# STM32U575xx register map
File version: 1.0
Registers are 32-bit, read-write, reset 0x0 unless marked. A register's access mark holds for its fields unless they carry their own. Offsets are from the block's base; [hi:lo] are bit positions; {n}, {i} and the like mark numbered series; 'fields as' and 'values as' point back to an identical list.

## FMC_Bank1E_R — Flexible Memory Controller Bank1E
Base 0x420D0504
Same registers: FMC_Bank1E_R_S 0x520D0504
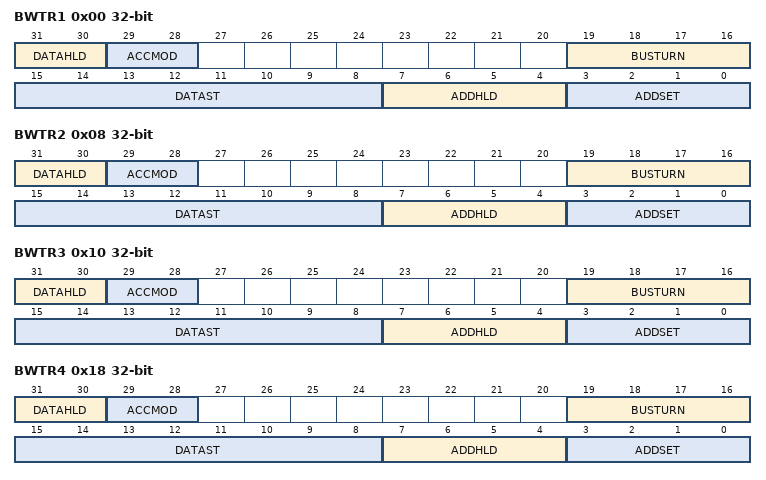
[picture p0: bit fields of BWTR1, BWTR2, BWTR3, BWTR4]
0x00 BWTR1 — NOR/PSRAM write timing registers
  [31:30] DATAHLD — DATAHLD[1:0] bits (Data hold phase duration)
  [29:28] ACCMOD — ACCMOD[1:0] bits (Access mode)
  [19:16] BUSTURN — BUSTURN[3:0] bits (Bus turnaround phase duration)
  [15:8] DATAST — DATAST [3:0] bits (Data-phase duration)
  [7:4] ADDHLD — ADDHLD[3:0] bits (Address-hold phase duration)
  [3:0] ADDSET — ADDSET[3:0] bits (Address setup phase duration)
0x08 BWTR2 — NOR/PSRAM write timing registers
  fields as BWTR1
0x10 BWTR3 — NOR/PSRAM write timing registers
  fields as BWTR1
0x18 BWTR4 — NOR/PSRAM write timing registers
  fields as BWTR1

## SYSCFG — System configuration controller
Base 0x46000400
Same registers: SYSCFG_S 0x56000400
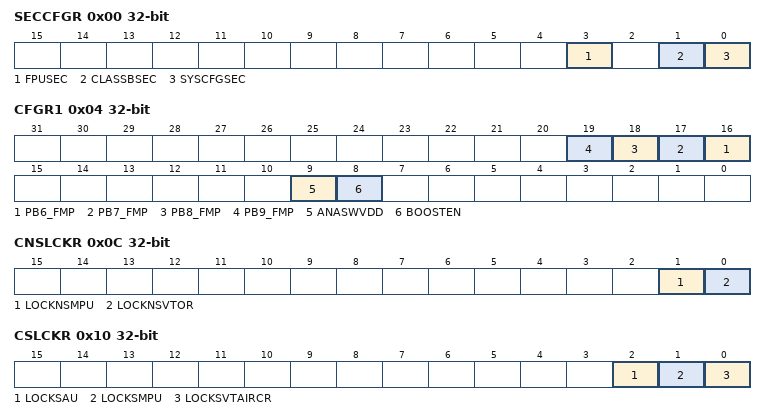
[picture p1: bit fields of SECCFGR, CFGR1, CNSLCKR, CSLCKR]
0x00 SECCFGR — SYSCFG secure configuration register
  [3] FPUSEC — FPU SYSCFG security enable
  [1] CLASSBSEC — ClassB SYSCFG security enable
  [0] SYSCFGSEC — SYSCFG clock control security enable
0x04 CFGR1 — SYSCFG configuration register 1
  [n+10] PB{n}_FMP (n=6..9) — PB{n} Fast mode plus
  [9] ANASWVDD — GPIO analog switch control voltage selection
  [8] BOOSTEN — I/O analog switch voltage booster enable
0x08 FPUIMR — SYSCFG FPU interrupt mask register
  [5:0] FPU_IE — All FPU interrupts enable
0x0C CNSLCKR — SYSCFG CPU non-secure lock register
  [1] LOCKNSMPU — Disable Non-Secure MPU registers writes by SW or debug agent
  [0] LOCKNSVTOR — Disable VTOR_NS register writes by SW or debug agent
0x10 CSLCKR — SYSCFG CPU secure lock register
  [2] LOCKSAU — Disable changes to SAU registers
  [1] LOCKSMPU — Disable changes to the secure MPU registers writes by SW or debug agent
  [0] LOCKSVTAIRCR — Disable changes to the secure vector table address, handling of system faults
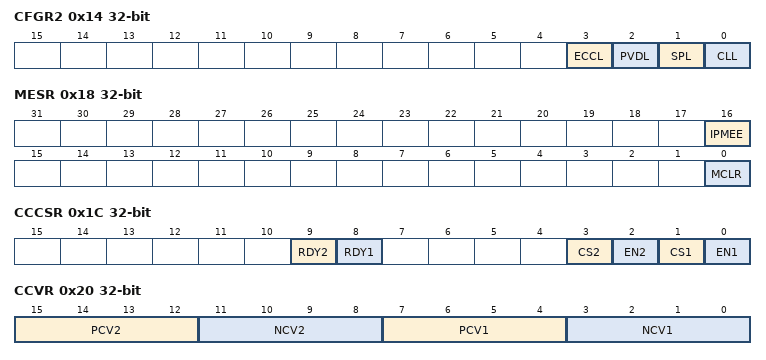
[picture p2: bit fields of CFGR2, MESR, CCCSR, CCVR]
0x14 CFGR2 — SYSCFG configuration register 2
  [3] ECCL — ECC Lock
  [2] PVDL — PVD Lock
  [1] SPL — SRAM ECC Lock
  [0] CLL — Core Lockup Lock
0x18 MESR — SYSCFG Memory Erase Status register
  [16] IPMEE — Status of End of Erase for ICache and PKA RAMs
  [0] MCLR — Status of Erase after Reset
0x1C CCCSR — SYSCFG Conpensaion Cell Control&Status register
  [9] RDY2 — VDDIO compensation cell ready flag
  [8] RDY1 — VDD compensation cell ready flag
  [3] CS2 — Code selection for VDDIO power rail
  [2] EN2 — Enable compensation cell for VDDIO power rail
  [1] CS1 — Code selection for VDD power rail
  [0] EN1 — Enable compensation cell for VDD power rail
0x20 CCVR — SYSCFG Conpensaion Cell value register
  [15:12] PCV2 — PMOS compensation value for VDDIO Power Rail
  [11:8] NCV2 — NMOS compensation value for VDDIO Power Rail
  [7:4] PCV1 — PMOS compensation value for VDD Power Rail
  [3:0] NCV1 — NMOS compensation value for VDD Power Rail
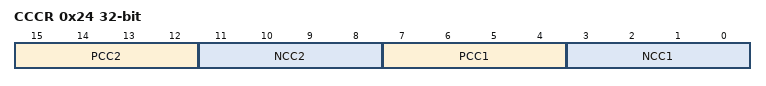
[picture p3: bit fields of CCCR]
0x24 CCCR — SYSCFG Conpensaion Cell Code register
  [15:12] PCC2 — PMOS compensation code for VDDIO Power Rail
  [11:8] NCC2 — NMOS compensation code for VDDIO Power Rail
  [7:4] PCC1 — PMOS compensation code for VDD Power Rail
  [3:0] NCC1 — NMOS compensation code for VDD Power Rail
0x2C RSSCMDR — SYSCFG RSS command mode register
  [15:0] RSSCMD — RSS command

## OPAMP12_COMMON
Base 0x46005000
Same registers: OPAMP12_COMMON_S 0x56005000
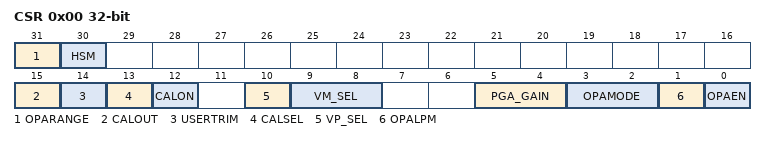
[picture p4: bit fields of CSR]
0x00 CSR — OPAMP control/status register, used for bits common to several OPAMP instances
  [31] OPARANGE — Operational amplifier range setting
    0=LOW (Power supply range low); 1=HIGH (Power supply range high - recommended for performance purpose)
  [30] HSM — Operational amplifier high speed mode
  [15] CALOUT — Operational amplifier calibration output
  [14] USERTRIM — User trimming enable
    0=FACTORY (OPAMP trimming factors set to factory values); 1=USER (OPAMP trimming factors set to user values)
  [13] CALSEL — Calibration selection
  [12] CALON — Calibration mode enable
    0=FUNCTIONAL (OPAMP functional mode); 1=CALIBRATION (OPAMP calibration mode)
  [10] VP_SEL — Non inverted input selection
    0=IO0 (OPAMP non inverting input connected to GPIO pin (pin PA0 for OPAMP1, pin PA6 for OPAMP2)); 1=DAC (OPAMP non inverting input connected to DAC1 channel output(channel1 for OPAMP1, channel2 for OPAMP2))
  [9:8] VM_SEL — Inverting input selection
    0=IO0 (OPAMP inverting input connected to GPIO pin (valid also in PGA mode for filtering). Note: OPAMP inverting input is used with OPAMP in mode standalone or PGA with external capacitors for filtering circuit. Otherwise (OPAMP in mode follower), OPAMP inverting input is not used (not connected to GPIO pin).); 1=IO1 (OPAMP inverting input (low leakage input) connected to GPIO pin (available only on package BGA132). Note: OPAMP inverting input is used with OPAMP in mode standalone or PGA with external capacitors for filtering circuit. Otherwise (OPAMP in mode follower), OPAMP inverting input is not used (not connected to GPIO pin).); 2=CONNECT_NO (OPAMP inverting input not externally connected (intended for OPAMP in mode follower or PGA without external capacitors for filtering))
  [5:4] PGA_GAIN — Operational amplifier Programmable amplifier gain value
    0=GAIN_2 (OPAMP PGA gain 2); 1=GAIN_4 (OPAMP PGA gain 4); 2=GAIN_8 (OPAMP PGA gain 8); 3=GAIN_16 (OPAMP PGA gain 16)
  [3:2] OPAMODE — Operational amplifier PGA mode
    0=STANDALONE (OPAMP functional mode, OPAMP operation in standalone); 3=FOLLOWER (OPAMP functional mode, OPAMP operation in follower); 2=PGA (OPAMP functional mode, OPAMP operation in PGA)
  [1] OPALPM — Operational amplifier Low Power Mode
  [0] OPAEN — OPAMP enable
